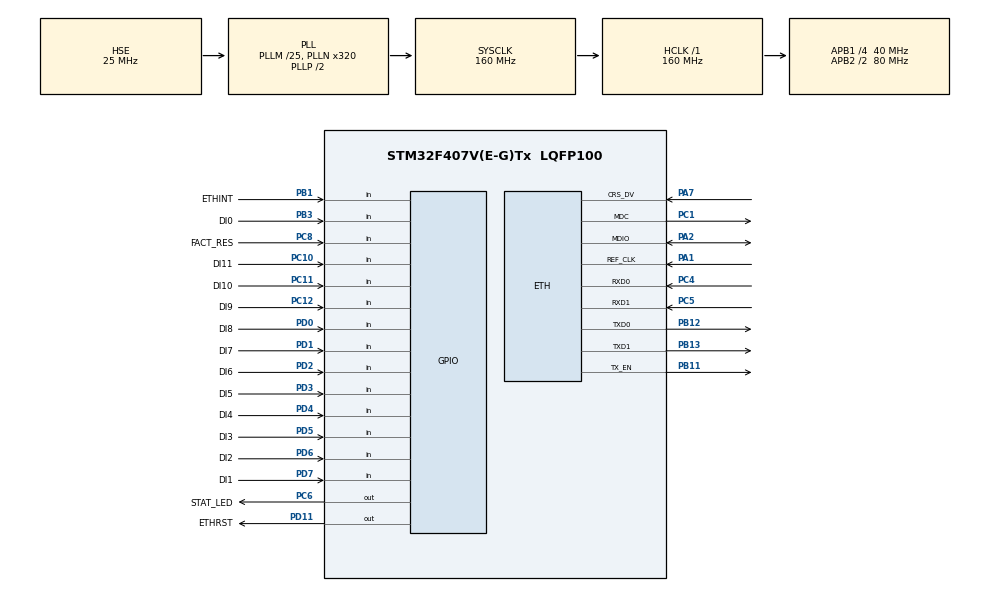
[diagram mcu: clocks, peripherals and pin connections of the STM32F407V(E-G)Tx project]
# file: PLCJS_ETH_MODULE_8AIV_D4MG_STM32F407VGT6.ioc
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ETH.MediaInterface=HAL_ETH_RMII_MODE
FREERTOS.Tasks01=defaultTask,24,128,StartDefaultTask,Default,NULL,Dynamic,NULL,NULL
FREERTOS.configTOTAL_HEAP_SIZE=20480
LWIP.BSP.number=1
LWIP.Version=v2.1.2_Cube
LWIP0.BSP.STBoard=false
LWIP0.BSP.api=BSP_COMPONENT_DRIVER
LWIP0.BSP.component=USER_PHY
LWIP0.BSP.instance=USER_PHY
LWIP0.BSP.name=Driver_PHY
LWIP0.BSP.semaphore=S_USER_PHY
LWIP0.BSP.solution=USER_PHY
Mcu.Family=STM32F4
Mcu.Name=STM32F407V(E-G)Tx
Mcu.Package=LQFP100
NVIC.ETH_IRQn=true\:5\:0\:false\:false\:true\:true\:false\:true\:true
NVIC.PriorityGroup=NVIC_PRIORITYGROUP_4
NVIC.TIM1_UP_TIM10_IRQn=true\:15\:0\:false\:false\:true\:false\:false\:true\:true
NVIC.TimeBase=TIM1_UP_TIM10_IRQn
NVIC.TimeBaseIP=TIM1
PA1.Mode=RMII
PA1.Signal=ETH_REF_CLK
PA13.Mode=Serial_Wire
PA13.Signal=SYS_JTMS-SWDIO
PA14.Mode=Serial_Wire
PA14.Signal=SYS_JTCK-SWCLK
PA2.Mode=RMII
PA2.Signal=ETH_MDIO
PA7.Mode=RMII
PA7.Signal=ETH_CRS_DV
PB1.GPIO_Label=ETHINT
PB1.Signal=GPIO_Input
PB11.Mode=RMII
PB11.Signal=ETH_TX_EN
PB12.Mode=RMII
PB12.Signal=ETH_TXD0
PB13.Mode=RMII
PB13.Signal=ETH_TXD1
PB3.GPIO_Label=DI0
PB3.Signal=GPIO_Input
PC1.Mode=RMII
PC1.Signal=ETH_MDC
PC10.GPIO_Label=DI11
PC10.Signal=GPIO_Input
PC11.GPIO_Label=DI10
PC11.Signal=GPIO_Input
PC12.GPIO_Label=DI9
PC12.Signal=GPIO_Input
PC4.Mode=RMII
PC4.Signal=ETH_RXD0
PC5.Mode=RMII
PC5.Signal=ETH_RXD1
PC6.GPIO_Label=STAT_LED
PC6.Signal=GPIO_Output
PC8.GPIO_Label=FACT_RES
PC8.GPIO_PuPd=GPIO_PULLUP
PC8.Signal=GPIO_Input
PD0.GPIO_Label=DI8
PD0.Signal=GPIO_Input
PD1.GPIO_Label=DI7
PD1.Signal=GPIO_Input
PD11.GPIO_Label=ETHRST
PD11.GPIO_PuPd=GPIO_NOPULL
PD11.Signal=GPIO_Output
PD2.GPIO_Label=DI6
PD2.Signal=GPIO_Input
PD3.GPIO_Label=DI5
PD3.Signal=GPIO_Input
PD4.GPIO_Label=DI4
PD4.Signal=GPIO_Input
PD5.GPIO_Label=DI3
PD5.Signal=GPIO_Input
PD6.GPIO_Label=DI2
PD6.Signal=GPIO_Input
PD7.GPIO_Label=DI1
PD7.Signal=GPIO_Input
PH0-OSC_IN.Mode=HSE-External-Oscillator
PH0-OSC_IN.Signal=RCC_OSC_IN
PH1-OSC_OUT.Mode=HSE-External-Oscillator
PH1-OSC_OUT.Signal=RCC_OSC_OUT
ProjectManager.HeapSize=0x200
ProjectManager.StackSize=0x400
ProjectManager.TargetToolchain=CMake
RCC.48MHZClocksFreq_Value=80000000
RCC.AHBFreq_Value=160000000
RCC.APB1CLKDivider=RCC_HCLK_DIV4
RCC.APB1Freq_Value=40000000
RCC.APB1TimFreq_Value=80000000
RCC.APB2CLKDivider=RCC_HCLK_DIV2
RCC.APB2Freq_Value=80000000
RCC.APB2TimFreq_Value=160000000
RCC.CortexFreq_Value=160000000
RCC.HCLKFreq_Value=160000000
RCC.HSE_VALUE=25000000
RCC.HSI_VALUE=16000000
RCC.LSE_VALUE=32768
RCC.PLLM=25
RCC.PLLN=320
RCC.PLLSourceVirtual=RCC_PLLSOURCE_HSE
RCC.SYSCLKFreq_VALUE=160000000
RCC.SYSCLKSource=RCC_SYSCLKSOURCE_PLLCLK
RCC.VCOOutputFreq_Value=320000000
VP_FREERTOS_VS_CMSIS_V2.Mode=CMSIS_V2
VP_IWDG_VS_IWDG.Mode=IWDG_Activate
VP_LWIP_VS_Enabled.Mode=Enabled
VP_SYS_VS_tim1.Mode=TIM1
board=custom

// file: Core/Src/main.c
/* USER CODE BEGIN Header */
/**
  ******************************************************************************
  * @file           : main.c
  * @brief          : Main program body
  ******************************************************************************
  * @attention
  *
  * Copyright (c) 2026 STMicroelectronics.
  * All rights reserved.
  *
  * This software is licensed under terms that can be found in the LICENSE file
  * in the root directory of this software component.
  * If no LICENSE file comes with this software, it is provided AS-IS.
  *
  ******************************************************************************
  */
/* USER CODE END Header */
#include "main.h"
#include "cmsis_os.h"
#include "iwdg.h"
#include "lwip.h"
#include "gpio.h"

/* USER CODE BEGIN Includes */
#include "board_pins.h"
#include "ksz8863.h"
/* USER CODE END Includes */

void SystemClock_Config(void);
void MX_FREERTOS_Init(void);

int main(void)
{

  /* USER CODE BEGIN 1 */
  /* 8AIV: CS_ADC = 1, SCLK = 0 before anything else. */
  board_early_pins();
  /* USER CODE END 1 */

  /* MCU Configuration--------------------------------------------------------*/

  /* Reset of all peripherals, Initializes the Flash interface and the Systick. */
  HAL_Init();

  /* Configure the system clock */
  SystemClock_Config();

  /* Initialize all configured peripherals */
  MX_GPIO_Init();
  MX_IWDG_Init();
  /* USER CODE BEGIN 2 */
  /* KSZ8863 boot policy: hardware-reset the switch only on a cold boot
   * (power-on / brown-out). On warm reboots (soft reset, IWDG, NRST) the
   * switch keeps forwarding pass-through traffic between its external ports
   * and must not be disturbed. */
  ksz8863_boot_init();
  /* USER CODE END 2 */

  /* Init scheduler */
  osKernelInitialize();  /* Call init function for freertos objects (in cmsis_os2.c) */
  MX_FREERTOS_Init();

  /* Start scheduler */
  osKernelStart();

  /* We should never get here as control is now taken by the scheduler */

  /* Infinite loop */
  while (1)
  {

  }
}

void SystemClock_Config(void)
{
  RCC_OscInitTypeDef RCC_OscInitStruct = {0};
  RCC_ClkInitTypeDef RCC_ClkInitStruct = {0};

  /** Configure the main internal regulator output voltage
  */
  __HAL_RCC_PWR_CLK_ENABLE();
  __HAL_PWR_VOLTAGESCALING_CONFIG(PWR_REGULATOR_VOLTAGE_SCALE1);

  /** Initializes the RCC Oscillators according to the specified parameters
  * in the RCC_OscInitTypeDef structure.
  */
  RCC_OscInitStruct.OscillatorType = RCC_OSCILLATORTYPE_LSI|RCC_OSCILLATORTYPE_HSE;
  RCC_OscInitStruct.HSEState = RCC_HSE_ON;
  RCC_OscInitStruct.LSIState = RCC_LSI_ON;
  RCC_OscInitStruct.PLL.PLLState = RCC_PLL_ON;
  RCC_OscInitStruct.PLL.PLLSource = RCC_PLLSOURCE_HSE;
  RCC_OscInitStruct.PLL.PLLM = 25;
  RCC_OscInitStruct.PLL.PLLN = 320;  /* 160 MHz: APB2 = 80 MHz -> SPI1 /8 = 10.0 MHz (8AIV ADC bus) */
  RCC_OscInitStruct.PLL.PLLP = RCC_PLLP_DIV2;
  RCC_OscInitStruct.PLL.PLLQ = 4;
  if (HAL_RCC_OscConfig(&RCC_OscInitStruct) != HAL_OK)
  {
    Error_Handler();
  }

  /** Initializes the CPU, AHB and APB buses clocks
  */
  RCC_ClkInitStruct.ClockType = RCC_CLOCKTYPE_HCLK|RCC_CLOCKTYPE_SYSCLK
                              |RCC_CLOCKTYPE_PCLK1|RCC_CLOCKTYPE_PCLK2;
  RCC_ClkInitStruct.SYSCLKSource = RCC_SYSCLKSOURCE_PLLCLK;
  RCC_ClkInitStruct.AHBCLKDivider = RCC_SYSCLK_DIV1;
  RCC_ClkInitStruct.APB1CLKDivider = RCC_HCLK_DIV4;
  RCC_ClkInitStruct.APB2CLKDivider = RCC_HCLK_DIV2;

  if (HAL_RCC_ClockConfig(&RCC_ClkInitStruct, FLASH_LATENCY_5) != HAL_OK)
  {
    Error_Handler();
  }
}

void HAL_TIM_PeriodElapsedCallback(TIM_HandleTypeDef *htim)
{
  if (htim->Instance == TIM1)
  {
    HAL_IncTick();
  }
}

void Error_Handler(void)
{
  __disable_irq();
  while (1)
  {
  }
}
